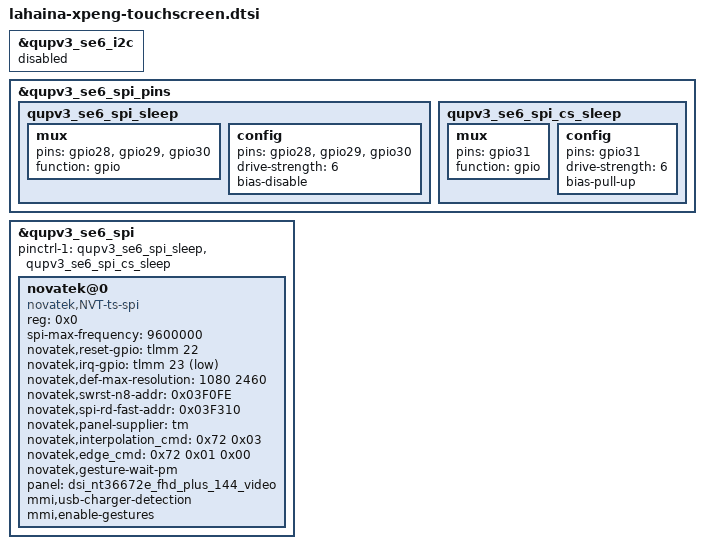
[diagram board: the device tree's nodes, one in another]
/*
 * Copyright (c) 2019, The Linux Foundation. All rights reserved.
 *
 * This program is free software; you can redistribute it and/or modify
 * it under the terms of the GNU General Public License version 2 and
 * only version 2 as published by the Free Software Foundation.
 *
 * This program is distributed in the hope that it will be useful,
 * but WITHOUT ANY WARRANTY; without even the implied warranty of
 * MERCHANTABILITY or FITNESS FOR A PARTICULAR PURPOSE.  See the
 * GNU General Public License for more details.
 */

&qupv3_se6_i2c {
	status = "disabled";
};

&qupv3_se6_spi_pins {
	qupv3_se6_spi_sleep: qupv3_se6_spi_sleep {
		mux {
			pins = "gpio28", "gpio29", "gpio30";
			function = "gpio";
		};

		config {
			pins = "gpio28", "gpio29", "gpio30";
			drive-strength = <6>;
			bias-disable;
		};
	};

	qupv3_se6_spi_cs_sleep: qupv3_se6_spi_cs_sleep {
		mux {
			pins = "gpio31";
			function = "gpio";
		};

		config {
			pins = "gpio31";
			drive-strength = <6>;
			bias-pull-up;
		};
	};
};

&qupv3_se6_spi {
	status = "ok";
	pinctrl-1 = <&qupv3_se6_spi_sleep &qupv3_se6_spi_cs_sleep>;
	novatek@0{
		compatible = "novatek,NVT-ts-spi";
		reg = <0x0>;
		spi-max-frequency = <9600000>;  /* 4800000,9600000,15000000,19200000 */
		novatek,reset-gpio = <&tlmm 22 0x00>;
		novatek,irq-gpio = <&tlmm 23 0x2001>;
		novatek,def-max-resolution = <1080 2460>;
		novatek,swrst-n8-addr = <0x03F0FE>;
		novatek,spi-rd-fast-addr = <0x03F310>;
		novatek,panel-supplier = "tm";
		novatek,interpolation_cmd = /bits/ 8 <0x72 0x03>;
		//novatek,jitter_cmd = /bits/ 8 <0x72 0x02>;
		//novatek,first_filter_cmd = /bits/ 8 <0x72 0x02>;
		novatek,edge_cmd = /bits/ 8 <0x72 0x01 0x00>;
		novatek,gesture-wait-pm;
		panel = <&dsi_nt36672e_fhd_plus_144_video>;
		status = "ok";
		/* touchscreen_mmi class entries */
		//mmi,class-entry-name = "NVT-ts";
		mmi,usb-charger-detection;
		mmi,enable-gestures;
	};
};
